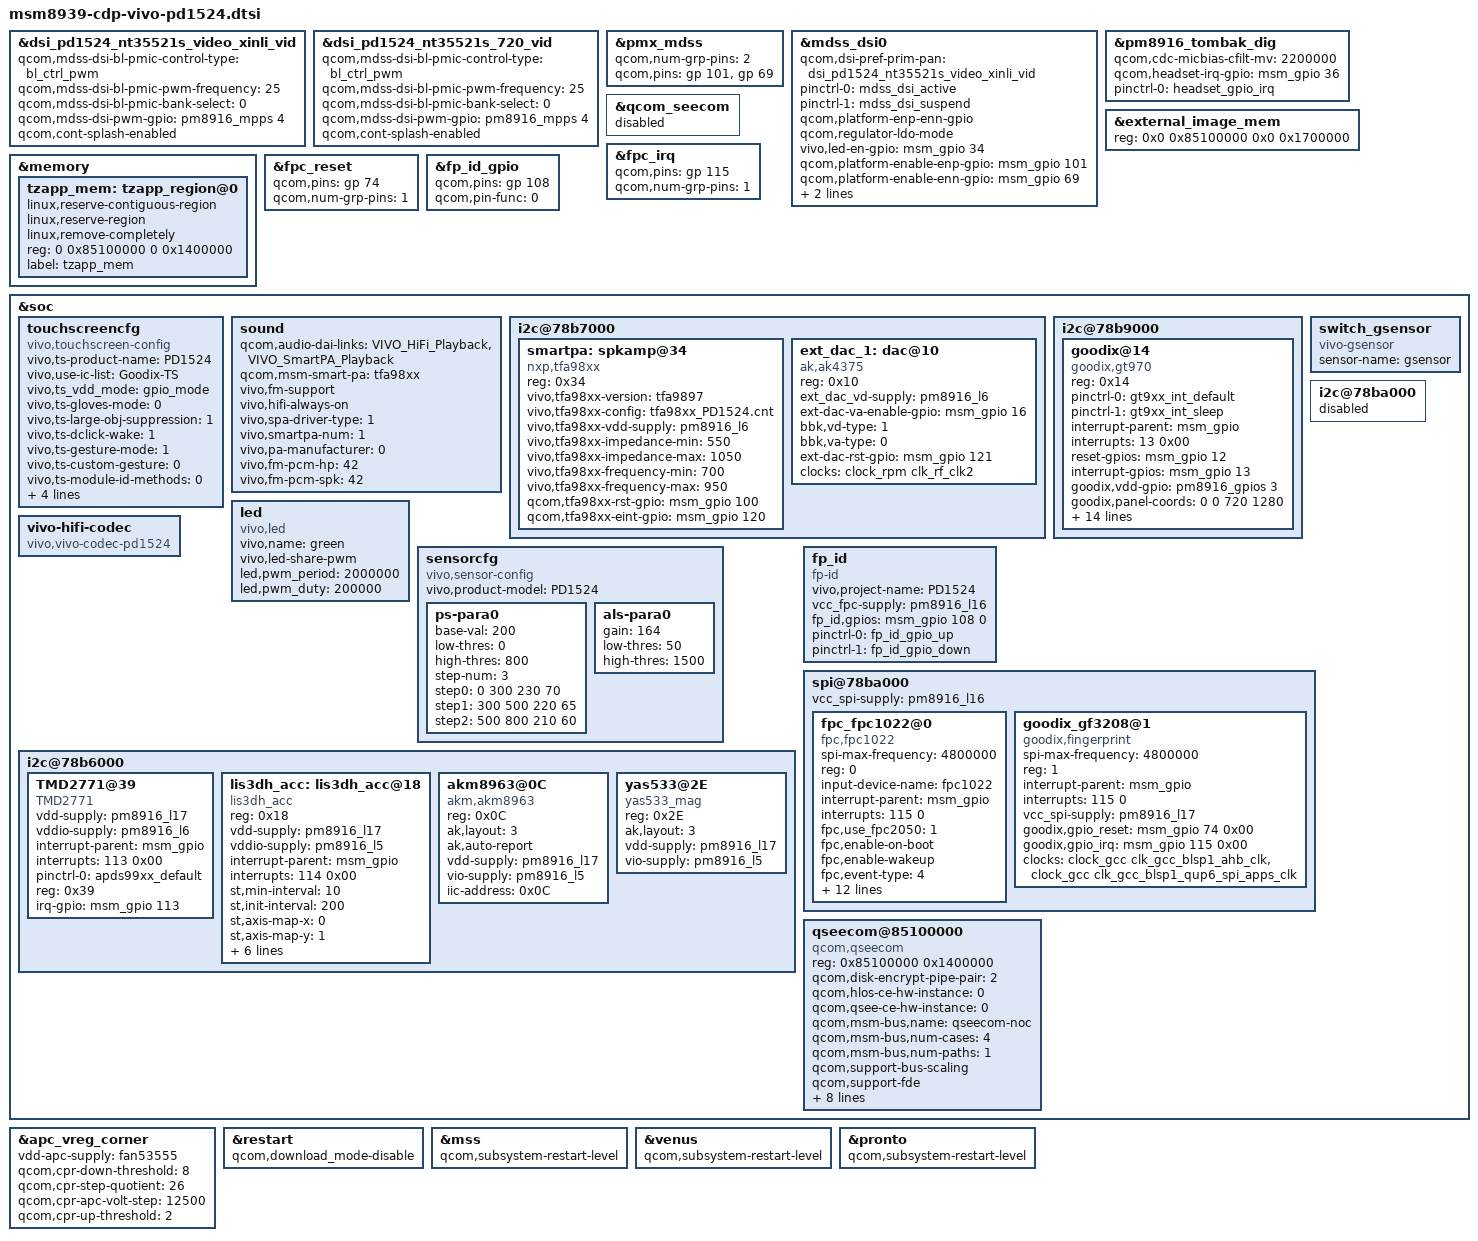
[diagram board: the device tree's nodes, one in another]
/* Copyright (c) 2014-2015, The Linux Foundation. All rights reserved.
 *
 * This program is free software; you can redistribute it and/or modify
 * it under the terms of the GNU General Public License version 2 and
 * only version 2 as published by the Free Software Foundation.
 *
 * This program is distributed in the hope that it will be useful,
 * but WITHOUT ANY WARRANTY; without even the implied warranty of
 * MERCHANTABILITY or FITNESS FOR A PARTICULAR PURPOSE.  See the
 * GNU General Public License for more details.
 */

#include "dsi-panel-pd1524-nt35521-720p-tianma.dtsi"
#include "dsi-panel-pd1524-nt35521-720p-xinli.dtsi"

&dsi_pd1524_nt35521s_video_xinli_vid {
	qcom,mdss-dsi-bl-pmic-control-type = "bl_ctrl_pwm";
	qcom,mdss-dsi-bl-pmic-pwm-frequency = <25>;
	qcom,mdss-dsi-bl-pmic-bank-select = <0>;
	qcom,mdss-dsi-pwm-gpio = <&pm8916_mpps 4 0>;
	qcom,cont-splash-enabled;
};

&dsi_pd1524_nt35521s_720_vid {
	qcom,mdss-dsi-bl-pmic-control-type = "bl_ctrl_pwm";
	qcom,mdss-dsi-bl-pmic-pwm-frequency = <25>;
	qcom,mdss-dsi-bl-pmic-bank-select = <0>;
	qcom,mdss-dsi-pwm-gpio = <&pm8916_mpps 4 0>;
	qcom,cont-splash-enabled;
};

&pmx_mdss {
	qcom,num-grp-pins = <2>;
	qcom,pins = <&gp 101>, <&gp 69>;
};

&mdss_dsi0 {
	qcom,dsi-pref-prim-pan = <&dsi_pd1524_nt35521s_video_xinli_vid>;
	pinctrl-names = "mdss_default", "mdss_sleep";
	pinctrl-0 = <&mdss_dsi_active>;
	pinctrl-1 = <&mdss_dsi_suspend>;
	
	qcom,platform-enp-enn-gpio;
	qcom,regulator-ldo-mode;
	vivo,led-en-gpio=<&msm_gpio 34 0>;
	qcom,platform-enable-enp-gpio = <&msm_gpio 101 0>;
	qcom,platform-enable-enn-gpio = <&msm_gpio 69 0>;
	qcom,platform-reset-gpio = <&msm_gpio 25 0>;
	qcom,platform-bklight-en-gpio = <&msm_gpio 102 0>;
}; 

&pm8916_tombak_dig{ /* audio headset detection */
		qcom,cdc-micbias-cfilt-mv = <2200000>;
		qcom,headset-irq-gpio = <&msm_gpio 36 0>;
		pinctrl-names = "headset_gpio_irq";
		pinctrl-0 = <&headset_gpio_irq>;
	};

&external_image_mem{
	reg = <0x0 0x85100000 0x0 0x1700000>;
};
&qcom_seecom {
	status = "disabled";
};
&memory {
		tzapp_mem: tzapp_region@0 {
			linux,reserve-contiguous-region;
			linux,reserve-region;
			linux,remove-completely;
			reg = <0 0x85100000 0 0x1400000>;
			label = "tzapp_mem";
		};
};

&fpc_irq {
			qcom,pins = <&gp 115>;
			qcom,num-grp-pins = <1>;
};

&fpc_reset {
			qcom,pins = <&gp 74>;
			qcom,num-grp-pins = <1>;
};

&fp_id_gpio{
			qcom,pins = <&gp 108>;
			qcom,pin-func = <0>;
};

&soc{
	touchscreencfg { /* vivo ts configure */
	   compatible = "vivo,touchscreen-config";
	   vivo,ts-product-name="PD1524";
	   vivo,use-ic-list="Goodix-TS";
	   vivo,ts_vdd_mode="gpio_mode"; /*regulator_mode or gpio_mode*/

	   
	   /*----- function set BEG ---- */
	   vivo,ts-gloves-mode=<0>;
	   vivo,ts-large-obj-suppression=<1>;
	   vivo,ts-dclick-wake=<1>;
	   vivo,ts-gesture-mode=<1>; /*1=sold in native,2=sold in abroad,3...etc=for custom extensive*/
	   vivo,ts-custom-gesture=<0>;
	   vivo,ts-module-id-methods=<0>;/*0=by IC id,1=gpio,2=by LCD ID 3=...etc=for custom extensive*/
	   vivo,ts-fw-upgrade-lcd-referrence=<0>;
	   vivo,ts-anti-esd=<1>;
	   vivo,ts-charger-conn-judge=<1>;
	   vivo,ts-module-smt-mode=<1>; /* 0=COB,1=COF */
	   /*----- function set END ---- */

	};

	sound {
		qcom,audio-dai-links =
			"VIVO_HiFi_Playback",
			"VIVO_SmartPA_Playback";
		qcom,msm-smart-pa = "tfa98xx";
		/* Sound card info */
		vivo,fm-support;
		vivo,hifi-always-on;
		vivo,spa-driver-type = <1>;
		vivo,smartpa-num = <1>;
		vivo,pa-manufacturer = <0>;
		vivo,fm-pcm-hp = <42>;
		vivo,fm-pcm-spk = <42>;
	};
	i2c@78b7000 {/* vivo audio */
		status = "okay";
		/* tfa9897 i2c */
		smartpa:spkamp@34 {
		compatible = "nxp,tfa98xx";
		reg = <0x34>;
		vivo,tfa98xx-version = "tfa9897";
		vivo,tfa98xx-config = "tfa98xx_PD1524.cnt";
		vivo,tfa98xx-vdd-supply = <&pm8916_l6>;
		vivo,tfa98xx-impedance-min = <550>;
		vivo,tfa98xx-impedance-max = <1050>;
		vivo,tfa98xx-frequency-min = <700>;
		vivo,tfa98xx-frequency-max = <950>;
		qcom,tfa98xx-rst-gpio = <&msm_gpio 100 0>;
		qcom,tfa98xx-eint-gpio = <&msm_gpio 120 0>;
		};
		/* ak4375 i2c */
		ext_dac_1: dac@10 {
	        compatible = "ak,ak4375";
	        reg = <0x10>;
	        ext_dac_vd-supply = <&pm8916_l6>;
	        ext-dac-va-enable-gpio = <&msm_gpio 16 0>;
	        bbk,vd-type  = <1>;
	        bbk,va-type  = <0>;
	        ext-dac-rst-gpio = <&msm_gpio 121 0>;
	        clocks = <&clock_rpm clk_rf_clk2>;
	        clock-names = "ref_clk";
		};
	};
	i2c@78b9000 { /* BLSP1 QUP5 */
        status = "ok";
		goodix@14 { //gt970L
			compatible = "goodix,gt970";
			reg = <0x14>;
			/* pins used by touchscreen */
			pinctrl-names = "gt9xx_int_default","gt9xx_int_suspend";
            		pinctrl-0 = <&gt9xx_int_default>;
            		pinctrl-1 = <&gt9xx_int_sleep>;
			interrupt-parent = <&msm_gpio>;
			interrupts = <13 0x00>;
			reset-gpios = <&msm_gpio 12 0x00>;
			interrupt-gpios = <&msm_gpio 13 0x00>;
            //vcc_i2c-supply = <&pm8916_l6>;
            //vdd-supply = <&pm8916_l16>;/* <&tp_power>;*/
			goodix,vdd-gpio = <&pm8916_gpios 3 0>;
			goodix,panel-coords = <0 0 720 1280>;
			goodix,display-coords = <0 0 720 1280>;
			goodix,button-map= <158 102 139>;
			goodix,family-id = <0x0>;
           		goodix,i2c-pull-up;
			goodix,cfg-data0 =    //jiemian
			[
				44 D0 02 5F 05 0A 34 D0 01 08 
				3C 08 50 32 30 35 00 00 37 13 
				10 01 00 14 14 26 14 8C 2C 0D 
				30 32 9D 09 9D 09 00 BA 33 11 
				00 00 00 00 00 00 00 08 0A A0 
				22 19 5A 54 D0 03 8C 1E 06 04 
				C9 1C 00 9E 25 23 82 2F 00 6A 
				3D 00 59 4F 00 59 00 00 00 00 
				00 00 00 00 00 00 00 00 00 00 
				00 00 00 00 FF 01 00 00 00 00 
				00 00 00 00 00 0F 50 00 00 00 
				00 1E 02 0C 04 0A 06 08 14 12 
				16 10 18 0E 1A FF 00 98 FB 1E 
				AC 1E 19 14 08 1E 87 00 DC 00 
				40 41 00 02 04 06 08 0A 0C 0F 
				10 12 13 14 16 18 1C 1D 1E 1F 
				20 21 22 24 26 28 FF FF 00 00 
				00 00 00 00 00 00 00 00 00 00 
				00 00 00 05 EE 01
			];                                         
			
			goodix,cfg-data2 =    //yeji
			[
				41 D0 02 5F 05 0A 34 00 01 08 
				32 08 50 3C 33 35 00 00 37 13 
				00 00 00 14 14 26 14 8C 2C 0D 
				3C 3E 9A 07 D3 07 00 99 33 11 
				00 00 00 00 00 00 00 00 00 00 
				21 1E 64 94 40 02 BC 1E 00 04 
				D0 22 00 A9 2B 1E 89 37 00 71 
				46 00 5E 59 00 5E 00 00 00 00 
				00 00 00 00 00 00 00 00 00 00 
				00 00 00 00 FF 01 00 00 00 00 
				00 00 00 00 00 0F 50 00 00 00 
				00 1E 02 0C 04 0A 06 08 14 12 
				16 10 18 0E 1A FF 00 00 00 00 
				00 00 00 00 00 00 00 00 04 00 
				50 00 00 02 04 06 08 0A 0C 0F 
				10 12 13 14 16 18 1C 1D 1E 1F 
				20 21 22 24 26 28 FF FF 00 00 
				00 00 00 00 00 00 00 00 00 00 
				00 00 00 00 8B 01
			];              
			
			goodix,cfg-data3 =    //lansi
			[
				41 D0 02 5F 05 0A 34 00 01 08 
				32 08 50 3C 33 35 00 00 37 13 
				00 00 00 14 14 26 14 8C 2C 0D 
				3C 3E 9A 07 D3 07 00 99 33 11 
				00 00 00 00 00 00 00 00 00 00 
				21 1E 64 94 40 02 BC 1E 00 04 
				D0 22 00 A9 2B 1E 89 37 00 71 
				46 00 5E 59 00 5E 00 00 00 00 
				00 00 00 00 00 00 00 00 00 00 
				00 00 00 00 FF 01 00 00 00 00 
				00 00 00 00 00 0F 50 00 00 00 
				00 1E 02 0C 04 0A 06 08 14 12 
				16 10 18 0E 1A FF 00 00 00 00 
				00 00 00 00 00 00 00 00 04 00 
				50 00 00 02 04 06 08 0A 0C 0F 
				10 12 13 14 16 18 1C 1D 1E 1F 
				20 21 22 24 26 28 FF FF 00 00 
				00 00 00 00 00 00 00 00 00 00 
				00 00 00 00 8B 01
			];                                   
				
			ts-suspend-resume=<0>;
			ts-fixed-key-type=<1>; /*0=0d,1=2d */
			
			/*--virtualkeys: EV_KEY:KEY_MENU:cx:cy:w:h:EV_KEY:KEY_HOMEPAGE:cx:cy:w:h:EV_KEY:KEY_BACK:cx:cy:w:h--*/
			ts-virt-key="0x01:139:117:1345:130:100:0x01:251:228:1345:90:100:0x01:172:360:1345:140:100:0x01:251:491:1345:90:100:0x01:158:603:1345:130:100";
};
	};
	led {
		compatible = "vivo,led";
		vivo,name = "green";
		vivo,led-share-pwm;
		led,pwm_period=<2000000>;
		led,pwm_duty=<200000>;
	};
	vivo-hifi-codec {
		compatible = "vivo,vivo-codec-pd1524";
	};
	sensorcfg {
		compatible = "vivo,sensor-config";
		vivo,product-model = "PD1524";
		ps-para0 {
			base-val = <200>;
			low-thres = <0>;
			high-thres = <800>;
			step-num = <3>;
			step0 = <  0 300 230 70>;
			step1 = <300 500 220 65>;
			step2 = <500 800 210 60>;
		};
		
		als-para0 {
			gain = <164>;
			low-thres = <50>;
			high-thres = <1500>;
		};
	};
	switch_gsensor {
		  compatible = "vivo-gsensor";
		  sensor-name = "gsensor";
		/*  sensor,gpio-irq = <&msm_gpio 21 0x00>;  */
	};
	i2c@78b6000 { /* BLSP1 QUP2 */
		TMD2771@39 {
			compatible = "TMD2771";
			vdd-supply = <&pm8916_l17>;
			vddio-supply = <&pm8916_l6>;
			interrupt-parent = <&msm_gpio>;
			interrupts = <113 0x00>;
			pinctrl-names = "default";
			pinctrl-0 = <&apds99xx_default>;
			reg = <0x39>;
			irq-gpio = <&msm_gpio 113 0x00>;
		};
		lis3dh_acc:lis3dh_acc@18 {
			compatible = "lis3dh_acc";
			reg = <0x18>;
			vdd-supply = <&pm8916_l17>;
			vddio-supply = <&pm8916_l5>;
			interrupt-parent = <&msm_gpio>;
			interrupts = <114 0x00>;
			st,min-interval = <10>;
			st,init-interval = <200>;
			st,axis-map-x = <0>;
			st,axis-map-y = <1>;
			st,axis-map-z = <2>;
			st,g-range = <2>;
			st,negate-x = <1>;
			st,negate-y = <0>;
			st,negate-z = <1>;
			sensor,gpio-irq = <&msm_gpio 114 0x00>;			
		};
		akm8963@0C {
			compatible = "akm,akm8963";
			reg = <0x0C>;
			ak,layout =<3>;
			ak,auto-report;
			vdd-supply = <&pm8916_l17>;
			vio-supply = <&pm8916_l5>;
			iic-address=<0x0C>;
		};
		yas533@2E {
			compatible = "yas533_mag";
			reg = <0x2E>;
			ak,layout =<3>;
			vdd-supply = <&pm8916_l17>;
			vio-supply = <&pm8916_l5>;
		};
	};
	
	fp_id:fp_id {
		compatible = "fp-id";
		status = "ok";
		vivo,project-name = "PD1524";
		vcc_fpc-supply  = <&pm8916_l16>;
		fp_id,gpios = <&msm_gpio 108 0>;
		pinctrl-names = "fp_gpio_pull_up",
						"fp_gpio_pull_down";
		pinctrl-0 = <&fp_id_gpio_up>;
		pinctrl-1 = <&fp_id_gpio_down>;
	};
	
	i2c@78ba000 { /* BLSP1 QUP6 */
		status = "disabled";
	};
	// add by gongyulong for fingerprint
	spi@78ba000 {
		status = "ok";
		vcc_spi-supply  = <&pm8916_l16>;
		
	    fpc_fpc1022@0 {
	    compatible = "fpc,fpc1022";
		spi-max-frequency = <4800000>;
	    reg = <0>;
	    input-device-name = "fpc1022";
	    interrupt-parent = <&msm_gpio>;
	    interrupts = <115 0>;

	    fpc,use_fpc2050 = <1>;
		fpc,enable-on-boot;
		fpc,enable-wakeup;
		fpc,event-type = <4>;
		fpc,event-code = <4>;
		spi-qup-id = <6>;
		vcc_spi-supply  = <&pm8916_l16>;
		vdd_ana-supply  = <&pm8916_l16>;
		vdd_io-supply   = <&pm8916_l16>;

	    fpc,gpio_reset = <&msm_gpio 74 0x00>;
		fpc,gpio_irq = <&msm_gpio 115 0x00>;

		clock-names = "iface_clk", "core_clk";
		clocks = <&clock_gcc clk_gcc_blsp1_ahb_clk>,
				<&clock_gcc clk_gcc_blsp1_qup6_spi_apps_clk>;

		pinctrl-names = "fpc1020_irq_active",
				"fpc1020_reset_active",
				"fpc1020_reset_reset";
		pinctrl-0 = <&fpc_irq_active>;
		pinctrl-1 = <&fpc_reset_active>;
		pinctrl-2 = <&fpc_reset_reset>;
		};
		
		goodix_gf3208@1 {
        compatible = "goodix,fingerprint";
        spi-max-frequency = <4800000>;
        reg = <1>;
        interrupt-parent = <&msm_gpio>;
        interrupts = <115 0>;

        vcc_spi-supply  = <&pm8916_l17>;

        goodix,gpio_reset = <&msm_gpio 74 0x00>;
        goodix,gpio_irq = <&msm_gpio 115 0x00>;

        clock-names = "iface_clk", "core_clk";
        clocks = <&clock_gcc clk_gcc_blsp1_ahb_clk>,
                <&clock_gcc clk_gcc_blsp1_qup6_spi_apps_clk>;
        };		
	};

	qseecom@85100000 {
		compatible = "qcom,qseecom";
		reg = <0x85100000 0x1400000>;
		reg-names = "secapp-region";
		qcom,disk-encrypt-pipe-pair = <2>;
		qcom,hlos-ce-hw-instance = <0>;
		qcom,qsee-ce-hw-instance = <0>;
		qcom,msm-bus,name = "qseecom-noc";
		qcom,msm-bus,num-cases = <4>;
		qcom,msm-bus,num-paths = <1>;
		qcom,support-bus-scaling;
		qcom,support-fde;
		qcom,msm-bus,vectors-KBps =
				<55 512 0 0>,
				<55 512 0 0>,
				<55 512 120000 1200000>,
				<55 512 393600 3936000>;
		clocks = <&clock_gcc clk_crypto_clk_src>,
			 <&clock_gcc clk_gcc_crypto_clk>,
			 <&clock_gcc clk_gcc_crypto_ahb_clk>,
			 <&clock_gcc clk_gcc_crypto_axi_clk>;
		clock-names = "core_clk_src", "core_clk",
				"iface_clk", "bus_clk";
		status = "ok";
		qcom,ce-opp-freq = <100000000>;
	}; 
};

&apc_vreg_corner {
		vdd-apc-supply = <&fan53555>;
		 qcom,cpr-down-threshold = <8>;
		 qcom,cpr-step-quotient = <26>;
		 qcom,cpr-apc-volt-step = <12500>;
		 qcom,cpr-up-threshold = <2>; 
};
&restart {
	qcom,download_mode-disable;
};
&mss {
	qcom,subsystem-restart-level;
};
&venus {
	qcom,subsystem-restart-level;
};
&pronto {
	qcom,subsystem-restart-level;
};

